# S6E1A1 register map
File version: 1.1
Registers are 8-bit, read-write, reset 0x0 unless marked. A register's access mark holds for its fields unless they carry their own. Offsets are from the block's base; [hi:lo] are bit positions; {n}, {i} and the like mark numbered series; 'fields as' and 'values as' point back to an identical list.

## MFS0 — MFS REgisters
Base 0x40038000
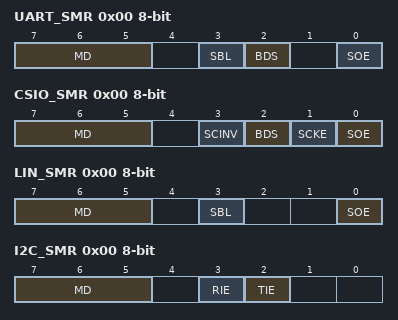
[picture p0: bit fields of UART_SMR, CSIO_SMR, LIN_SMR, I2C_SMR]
0x00 UART_SMR (UART view) — Serial Mode Register
  [7:5] MD — Operation mode set bit
  [3] SBL — Stop bit length select bit
  [2] BDS — Transfer direction select bit
  [0] SOE — Serial data output enable bit
0x00 CSIO_SMR (CSIO view) — Serial Mode Register
  [7:5] MD — Operation mode set bits
  [3] SCINV — Serial clock invert bit
  [2] BDS — Transfer direction select bit
  [1] SCKE — Master mode serial clock output enable bit
  [0] SOE — Serial data output enable bit
0x00 LIN_SMR (LIN view) — ERROR!!!!!!!!!!!!!!!!!!!!
  [7:5] MD — ERROR!!!!!!!!!!!!!!!!!!!!
  [3] SBL — ERROR!!!!!!!!!!!!!!!!!!!!
  [0] SOE — ERROR!!!!!!!!!!!!!!!!!!!!
0x00 I2C_SMR (I2C view) — ERROR!!!!!!!!!!!!!!!!!!!!
  [7:5] MD — ERROR!!!!!!!!!!!!!!!!!!!!
  [3] RIE — ERROR!!!!!!!!!!!!!!!!!!!!
  [2] TIE — ERROR!!!!!!!!!!!!!!!!!!!!
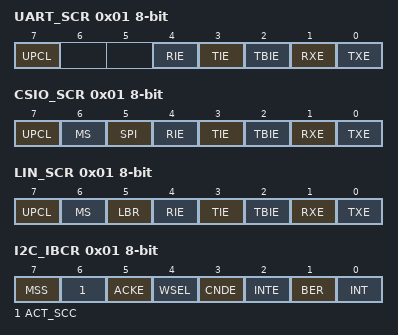
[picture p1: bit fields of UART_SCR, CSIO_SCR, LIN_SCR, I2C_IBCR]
0x01 UART_SCR (UART view) — Serial Control Register
  [7] UPCL — Programmable Clear bit
  [4] RIE — Received interrupt enable bit
  [3] TIE — Transmit interrupt enable bit
  [2] TBIE — Transmit bus idle interrupt enable bit
  [1] RXE — Received operation enable bit
  [0] TXE — Transmission operation enable bit
0x01 CSIO_SCR (CSIO view) — Serial Control Register
  [7] UPCL — Programmable clear bit
  [6] MS — Master/Slave function select bit
  [5] SPI — SPI corresponding bit
  [4] RIE — Received interrupt enable bit
  [3] TIE — Transmit interrupt enable bit
  [2] TBIE — Transmit bus idle interrupt enable bit
  [1] RXE — Data received enable bit
  [0] TXE — Data transmission enable bit
0x01 LIN_SCR (LIN view) — ERROR!!!!!!!!!!!!!!!!!!!!
  [7] UPCL — ERROR!!!!!!!!!!!!!!!!!!!!
  [6] MS — ERROR!!!!!!!!!!!!!!!!!!!!
  [5] LBR — ERROR!!!!!!!!!!!!!!!!!!!!
  [4] RIE — ERROR!!!!!!!!!!!!!!!!!!!!
  [3] TIE — ERROR!!!!!!!!!!!!!!!!!!!!
  [2] TBIE — ERROR!!!!!!!!!!!!!!!!!!!!
  [1] RXE — ERROR!!!!!!!!!!!!!!!!!!!!
  [0] TXE — ERROR!!!!!!!!!!!!!!!!!!!!
0x01 I2C_IBCR (I2C view) — ERROR!!!!!!!!!!!!!!!!!!!!
  [7] MSS — ERROR!!!!!!!!!!!!!!!!!!!!
  [6] ACT_SCC — ERROR!!!!!!!!!!!!!!!!!!!!
  [5] ACKE — ERROR!!!!!!!!!!!!!!!!!!!!
  [4] WSEL — ERROR!!!!!!!!!!!!!!!!!!!!
  [3] CNDE — ERROR!!!!!!!!!!!!!!!!!!!!
  [2] INTE — ERROR!!!!!!!!!!!!!!!!!!!!
  [1] BER ro — ERROR!!!!!!!!!!!!!!!!!!!!
  [0] INT — ERROR!!!!!!!!!!!!!!!!!!!!
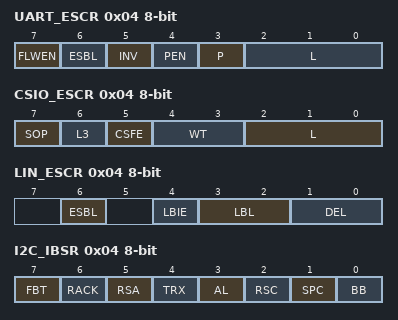
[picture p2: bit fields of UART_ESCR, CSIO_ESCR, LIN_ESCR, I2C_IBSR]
0x04 UART_ESCR (UART view) — Extended Communication Control Register
  [7] FLWEN — Flow control enable bit
  [6] ESBL — Extension stop bit length select bit
  [5] INV — Inverted serial data format bit
  [4] PEN — Parity enable bit (only functions in operation mode 0)
  [3] P — Parity select bit (only functions in operation mode 0)
  [2:0] L — Data length select bit
0x04 CSIO_ESCR (CSIO view) — Extended Communication Control Register
  [7] SOP — Serial output pin set bit
  [6] L3 — Bit3 of Data length select bits
  [5] CSFE — Serial Chip Select Format enable bit
  [4:3] WT — Data transmit/received wait select bits
  [2:0] L — Bit0-2 of Data length select bits
0x04 LIN_ESCR (LIN view) — ERROR!!!!!!!!!!!!!!!!!!!!
  [6] ESBL — ERROR!!!!!!!!!!!!!!!!!!!!
  [4] LBIE — ERROR!!!!!!!!!!!!!!!!!!!!
  [3:2] LBL — ERROR!!!!!!!!!!!!!!!!!!!!
  [1:0] DEL — ERROR!!!!!!!!!!!!!!!!!!!!
0x04 I2C_IBSR (I2C view) — ERROR!!!!!!!!!!!!!!!!!!!!
  [7] FBT ro — ERROR!!!!!!!!!!!!!!!!!!!!
  [6] RACK ro — ERROR!!!!!!!!!!!!!!!!!!!!
  [5] RSA ro — ERROR!!!!!!!!!!!!!!!!!!!!
  [4] TRX ro — ERROR!!!!!!!!!!!!!!!!!!!!
  [3] AL ro — ERROR!!!!!!!!!!!!!!!!!!!!
  [2] RSC — ERROR!!!!!!!!!!!!!!!!!!!!
  [1] SPC — ERROR!!!!!!!!!!!!!!!!!!!!
  [0] BB ro — ERROR!!!!!!!!!!!!!!!!!!!!
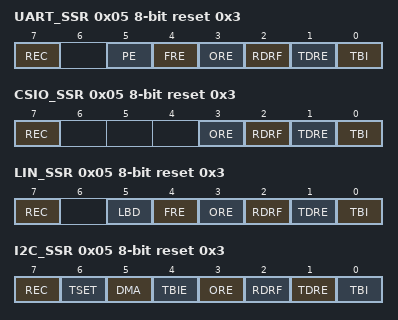
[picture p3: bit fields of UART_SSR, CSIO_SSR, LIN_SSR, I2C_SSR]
0x05 UART_SSR reset 0x3 (UART view) — Serial Status Register
  [7] REC — Received error flag clear bit
  [5] PE ro — Parity error flag bit
  [4] FRE ro — Framing error flag bit
  [3] ORE ro — Overrun error flag bit
  [2] RDRF ro — Received data full flag bit
  [1] TDRE ro — Transmit data empty flag bit
  [0] TBI ro — Transmit bus idle flag
0x05 CSIO_SSR reset 0x3 (CSIO view) — Serial Status Register
  [7] REC — Received error flag clear bit
  [3] ORE ro — Overrun error flag bit
  [2] RDRF ro — Received data full flag bit
  [1] TDRE ro — Transmit data empty flag bit
  [0] TBI ro — Transmit bus idle flag bit
0x05 LIN_SSR reset 0x3 (LIN view) — ERROR!!!!!!!!!!!!!!!!!!!!
  [7] REC — ERROR!!!!!!!!!!!!!!!!!!!!
  [5] LBD — ERROR!!!!!!!!!!!!!!!!!!!!
  [4] FRE ro — ERROR!!!!!!!!!!!!!!!!!!!!
  [3] ORE ro — ERROR!!!!!!!!!!!!!!!!!!!!
  [2] RDRF ro — ERROR!!!!!!!!!!!!!!!!!!!!
  [1] TDRE ro — ERROR!!!!!!!!!!!!!!!!!!!!
  [0] TBI ro — ERROR!!!!!!!!!!!!!!!!!!!!
0x05 I2C_SSR reset 0x3 (I2C view) — ERROR!!!!!!!!!!!!!!!!!!!!
  [7] REC — ERROR!!!!!!!!!!!!!!!!!!!!
  [6] TSET — ERROR!!!!!!!!!!!!!!!!!!!!
  [5] DMA — ERROR!!!!!!!!!!!!!!!!!!!!
  [4] TBIE — ERROR!!!!!!!!!!!!!!!!!!!!
  [3] ORE ro — ERROR!!!!!!!!!!!!!!!!!!!!
  [2] RDRF ro — ERROR!!!!!!!!!!!!!!!!!!!!
  [1] TDRE ro — ERROR!!!!!!!!!!!!!!!!!!!!
  [0] TBI ro — ERROR!!!!!!!!!!!!!!!!!!!!
0x08 UART_RDR 16-bit ro (reset mask 0x1FF) (UART view) — Received Data Register
0x08 UART_TDR 16-bit wo reset 0x1FF (reset mask 0x1FF) (UART view) — Transmit Data Register
0x08 CSIO_RDR 16-bit ro (CSIO view) — Received Data Register
0x08 CSIO_TDR 16-bit wo reset 0xFFFF (CSIO view) — Transmit Data Register
0x08 LIN_RDR 16-bit ro (reset mask 0xFF) (LIN view) — ERROR!!!!!!!!!!!!!!!!!!!!
0x08 LIN_TDR 16-bit wo reset 0xFF (reset mask 0xFF) (LIN view) — ERROR!!!!!!!!!!!!!!!!!!!!
0x08 I2C_RDR 16-bit ro (reset mask 0xFF) (I2C view) — ERROR!!!!!!!!!!!!!!!!!!!!
0x08 I2C_TDR 16-bit wo reset 0xFF (reset mask 0xFF) (I2C view) — ERROR!!!!!!!!!!!!!!!!!!!!
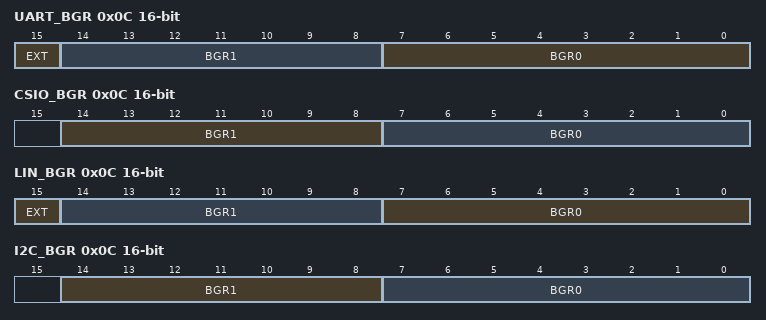
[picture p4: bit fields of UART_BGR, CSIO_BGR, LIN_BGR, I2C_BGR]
0x0C UART_BGR 16-bit (UART view) — Baud Rate Generator Registers
  [15] EXT — External clock select bit
  [14:8] BGR1 — Baud Rate Generator Register 1
  [7:0] BGR0 — Baud Rate Generator Register 0
0x0C CSIO_BGR 16-bit (CSIO view) — Baud Rate Generator Registers
  [14:8] BGR1 — Baud Rate Generator Register 1
  [7:0] BGR0 — Baud Rate Generator Register 0
0x0C LIN_BGR 16-bit (LIN view) — ERROR!!!!!!!!!!!!!!!!!!!!
  [15] EXT — ERROR!!!!!!!!!!!!!!!!!!!!
  [14:8] BGR1 — ERROR!!!!!!!!!!!!!!!!!!!!
  [7:0] BGR0 — ERROR!!!!!!!!!!!!!!!!!!!!
0x0C I2C_BGR 16-bit (I2C view) — ERROR!!!!!!!!!!!!!!!!!!!!
  [14:8] BGR1 — ERROR!!!!!!!!!!!!!!!!!!!!
  [7:0] BGR0 — ERROR!!!!!!!!!!!!!!!!!!!!
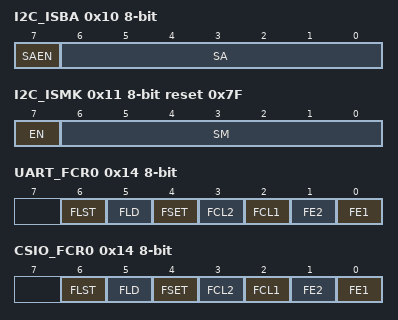
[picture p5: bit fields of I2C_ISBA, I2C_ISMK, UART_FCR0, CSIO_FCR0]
0x10 I2C_ISBA (I2C view) — ERROR!!!!!!!!!!!!!!!!!!!!
  [7] SAEN — ERROR!!!!!!!!!!!!!!!!!!!!
  [6:0] SA — ERROR!!!!!!!!!!!!!!!!!!!!
0x11 I2C_ISMK reset 0x7F (I2C view) — ERROR!!!!!!!!!!!!!!!!!!!!
  [7] EN — ERROR!!!!!!!!!!!!!!!!!!!!
  [6:0] SM — ERROR!!!!!!!!!!!!!!!!!!!!
0x14 UART_FCR0 (UART view) — FIFO Control Register 0
  [6] FLST ro — FIFO re-transmit data lost flag bit
  [5] FLD — FIFO pointer reload bit
  [4] FSET — FIFO pointer save bit
  [3] FCL2 — FIFO2 reset bit
  [2] FCL1 — FIFO1 reset bit
  [1] FE2 — FIFO2 operation enable bit
  [0] FE1 — FIFO1 operation enable bit
0x14 CSIO_FCR0 (CSIO view) — FIFO Control Register 0
  fields as UART_FCR0
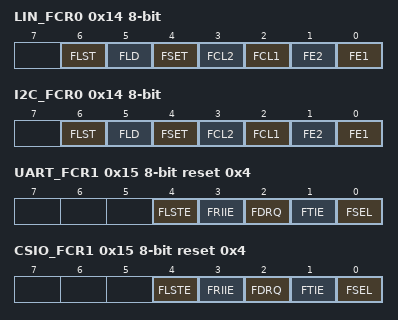
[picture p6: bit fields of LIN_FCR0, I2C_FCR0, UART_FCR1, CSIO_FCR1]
0x14 LIN_FCR0 (LIN view) — ERROR!!!!!!!!!!!!!!!!!!!!
  [6] FLST ro — ERROR!!!!!!!!!!!!!!!!!!!!
  [5] FLD — ERROR!!!!!!!!!!!!!!!!!!!!
  [4] FSET — ERROR!!!!!!!!!!!!!!!!!!!!
  [3] FCL2 — ERROR!!!!!!!!!!!!!!!!!!!!
  [2] FCL1 — ERROR!!!!!!!!!!!!!!!!!!!!
  [1] FE2 — ERROR!!!!!!!!!!!!!!!!!!!!
  [0] FE1 — ERROR!!!!!!!!!!!!!!!!!!!!
0x14 I2C_FCR0 (I2C view) — ERROR!!!!!!!!!!!!!!!!!!!!
  fields as LIN_FCR0
0x15 UART_FCR1 reset 0x4 (UART view) — FIFO Control Register 1
  [4] FLSTE — Re-transmission data lost detect enable bit
  [3] FRIIE — Received FIFO idle detection enable bit
  [2] FDRQ — Transmit FIFO data request bit
  [1] FTIE — Transmit FIFO interrupt enable bit
  [0] FSEL — FIFO select bit
0x15 CSIO_FCR1 reset 0x4 (CSIO view) — FIFO Control Register 1
  [4] FLSTE — Re-transmit data lost detect enable bit
  [3] FRIIE — Received FIFO idle detection enable bit
  [2] FDRQ — Transmit FIFO data request bit
  [1] FTIE — Transmit FIFO interrupt enable bit
  [0] FSEL — FIFO select bit
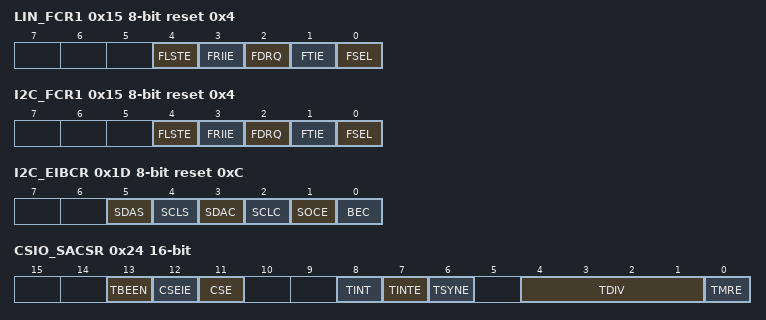
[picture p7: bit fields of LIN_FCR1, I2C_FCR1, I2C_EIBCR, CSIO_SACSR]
0x15 LIN_FCR1 reset 0x4 (LIN view) — ERROR!!!!!!!!!!!!!!!!!!!!
  [4] FLSTE — ERROR!!!!!!!!!!!!!!!!!!!!
  [3] FRIIE — ERROR!!!!!!!!!!!!!!!!!!!!
  [2] FDRQ — ERROR!!!!!!!!!!!!!!!!!!!!
  [1] FTIE — ERROR!!!!!!!!!!!!!!!!!!!!
  [0] FSEL — ERROR!!!!!!!!!!!!!!!!!!!!
0x15 I2C_FCR1 reset 0x4 (I2C view) — ERROR!!!!!!!!!!!!!!!!!!!!
  fields as LIN_FCR1
0x18 UART_FBYTE1 (UART view) — FIFO Byte Register 1
0x18 CSIO_FBYTE1 (CSIO view) — FIFO Byte Register 1
0x18 LIN_FBYTE1 (LIN view) — ERROR!!!!!!!!!!!!!!!!!!!!
0x18 I2C_FBYTE1 (I2C view) — ERROR!!!!!!!!!!!!!!!!!!!!
0x19 UART_FBYTE2 (UART view) — FIFO Byte Register 2
0x19 CSIO_FBYTE2 (CSIO view) — FIFO Byte Register 2
0x19 LIN_FBYTE2 (LIN view) — ERROR!!!!!!!!!!!!!!!!!!!!
0x19 I2C_FBYTE2 (I2C view) — ERROR!!!!!!!!!!!!!!!!!!!!
0x1C CSIO_SCSTR0 (CSIO view) — Serial Chip Select Timing Register 0
  [7:0] CSHD — Serial Chip Select Hold Delay bits
0x1D CSIO_SCSTR1 (CSIO view) — Serial Chip Select Timing Register 1
  [7:0] CSSU — Serial Chip Select Setup Delay bits
0x1D I2C_EIBCR reset 0xC (I2C view) — ERROR!!!!!!!!!!!!!!!!!!!!
  [5] SDAS ro — ERROR!!!!!!!!!!!!!!!!!!!!
  [4] SCLS ro — ERROR!!!!!!!!!!!!!!!!!!!!
  [3] SDAC — ERROR!!!!!!!!!!!!!!!!!!!!
  [2] SCLC — ERROR!!!!!!!!!!!!!!!!!!!!
  [1] SOCE — ERROR!!!!!!!!!!!!!!!!!!!!
  [0] BEC — ERROR!!!!!!!!!!!!!!!!!!!!
0x20 CSIO_SCSTR32 16-bit (CSIO view) — Serial Chip Select Timing Register 32
  [15:0] CSDS — Serial Chip Deselect bits
0x24 CSIO_SACSR 16-bit (CSIO view) — Serial Support Control Register
  [13] TBEEN — Transfer Byte Error Enable bit
  [12] CSEIE — Chip Select Error Interupt Enable bit
  [11] CSE — Chip Select Error Flag
  [8] TINT — Timer Interrupt Flag
  [7] TINTE — Timer Interrupt Enable bit
  [6] TSYNE — Synchronous Transmission Enable bit
  [4:1] TDIV — Timer Operation Clock Division bit
  [0] TMRE — Serial Timer Enable bit
0x28 CSIO_STMR 16-bit ro (CSIO view) — Serial Timer Register
  [15:0] TM — Timer Data bits
0x2C CSIO_STMCR 16-bit (CSIO view) — Serial Timer Comparison Register
  [15:0] TC — Compare bits
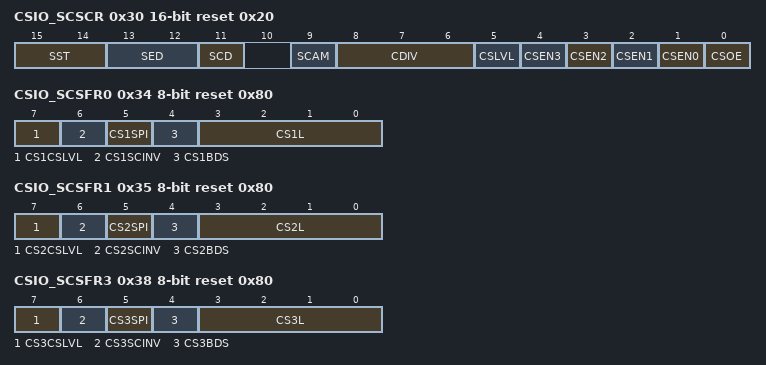
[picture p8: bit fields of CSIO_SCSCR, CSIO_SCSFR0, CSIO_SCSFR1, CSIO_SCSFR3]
0x30 CSIO_SCSCR 16-bit reset 0x20 (CSIO view) — Serial Chip Select Control Status Register
  [15:14] SST — Serial Chip Select Active Start bit
  [13:12] SED — Serial Chip Select Active End bit
  [11] SCD — Serial Chip Select Active Display bit
  [9] SCAM — Serial Chip Select Active Hold bit
  [8:6] CDIV — Serial Chip Select Timing Operation Clock Division bit
  [5] CSLVL — Serial Chip Select Level Setting bit
  [n+1] CSEN{n} (n=0..3) — Serial Chip Select Enable bit
  [0] CSOE — Serial Chip Select Output Enable bit
0x34 CSIO_SCSFR0 reset 0x80 — Serial Chip Select Format Register 0
  [7] CS1CSLVL — Serial Chip Select 1 Level Setting bit
  [6] CS1SCINV — Serial Clock Invert bit of Serial Chip Select 1
  [5] CS1SPI — SPI corresponding bit of Serial Chip Select 1
  [4] CS1BDS — Transfer direction select bit of Serial Chip Select 1
  [3:0] CS1L — Data length select bits of Serial Chip Select 1
0x35 CSIO_SCSFR1 reset 0x80 — Serial Chip Select Format Register 1
  [7] CS2CSLVL — Serial Chip Select 2 Level Setting bit
  [6] CS2SCINV — Serial Clock Invert bit of Serial Chip Select 2
  [5] CS2SPI — SPI corresponding bit of Serial Chip Select 2
  [4] CS2BDS — Transfer direction select bit of Serial Chip Select 2
  [3:0] CS2L — Data length select bits of Serial Chip Select 2
0x38 CSIO_SCSFR3 reset 0x80 — ERROR!!!!!!!!!!!!!!!!!!!!
  [7] CS3CSLVL — ERROR!!!!!!!!!!!!!!!!!!!!
  [6] CS3SCINV — ERROR!!!!!!!!!!!!!!!!!!!!
  [5] CS3SPI — ERROR!!!!!!!!!!!!!!!!!!!!
  [4] CS3BDS — ERROR!!!!!!!!!!!!!!!!!!!!
  [3:0] CS3L — ERROR!!!!!!!!!!!!!!!!!!!!
0x3C CSIO_TBYTE0 (CSIO view) — Transfer Byte Register 0
0x3D CSIO_TBYTE1 (CSIO view) — Transfer Byte Register 1
0x40 CSIO_TBYTE2 (CSIO view) — Transfer Byte Register 2
0x41 CSIO_TBYTE3 (CSIO view) — Transfer Byte Register 3
